# N571P032_v3 register map
File version: 1.0
Registers are 32-bit, read-write, reset 0x0 unless marked. A register's access mark holds for its fields unless they carry their own. Offsets are from the block's base; [hi:lo] are bit positions.

## SYS — SYS Register Map
Base 0x50000000
0x00 SYS_PDID ro reset 0xB320000 (reset mask 0xFFFF0000) — Product Identifier Register
  [15:0] IMG2 — Product Identifier. Data in MAP2 of information block are copied to this register after power on. MAP2 is used to store part number defined by Nuvoton.
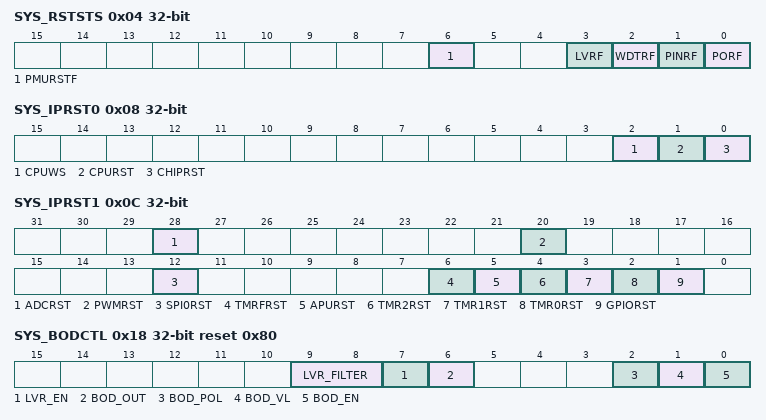
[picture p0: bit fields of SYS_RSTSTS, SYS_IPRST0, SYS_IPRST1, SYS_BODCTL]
0x04 SYS_RSTSTS (reset mask 0xFFFFFF00) — System Reset Source Register
  [6] PMURSTF — Reset Source From PMU. The PMURSTF flag is set by the reset signal from the PMU module to indicate the previous reset source. Note: Write 1 to clear this bit to 0.
    0=No reset from PMU; 1=The PMU has issued the reset signal to reset the system
  [3] LVRF — LVR Reset Flag. The LVR reset flag is set by the "Reset Signal" from the Low Voltage Reset Controller to indicate the previous reset source. Note: Write 1 to clear this bit to 0.
    0=No reset from LVR; 1=LVR controller had issued the reset signal to reset the system
  [2] WDTRF — Reset Source From WDG. The WDTRF flag is set if pervious reset source originates from the Watch-Dog module. Note: Write 1 to clear this bit to 0.
    0=No reset from Watch-Dog; 1=The Watch-Dog module issued the reset signal to reset the system
  [1] PINRF — nRESET Pin Reset Flag. The nRESET pin reset flag is set by the "Reset Signal" from the nRESET Pin to indicate the previous reset source. Note: Write 1 to clear this bit to 0.
    0=No reset from nRESET pin; 1=Pin nRESET had issued the reset signal to reset the system
  [0] PORF — POR Reset Flag. The POR reset flag is set by the "Reset Signal" from the Power-on Reset (POR) Controller to indicate the previous reset source. Note: Write 1 to clear this bit to 0.
    0=No reset from POR; 1=Power-on Reset (POR) Controller had issued the reset signal to reset the system
0x08 SYS_IPRST0 — IP Reset Control Resister0
  [2] CPUWS — CPU Wait-State Control For OTP Memory Access. Note: there must be 1 HCLK wait state if HCLK equal 23MHz.
    0=1 HCLK clock wait-state; 1=zero wait-state
  [1] CPURST — CPU Kernel One Shot Reset. Setting this bit will reset the CPU kernel and OTP Memory Controller(OMC), this bit will automatically return to "0" after the 2 clock cycles
    0=Normal; 1=Reset CPU
  [0] CHIPRST — CHIP One Shot Reset. Set this bit will reset the whole chip, this bit will automatically return to "0" after 2 clock cycles. CHIPRST is same as POR reset, all the chip modules are reset and the chip configuration settings from OTP are reloaded.
    0=Normal; 1=Reset CHIP
0x0C SYS_IPRST1 — IP Reset Control Resister1
  [28] ADCRST — ADC Controller Reset
    0=Normal Operation; 1=Reset
  [20] PWMRST — PWM Controller Reset
    0=Normal Operation; 1=Reset
  [12] SPI0RST — SPI0 Controller Reset
    0=Normal Operation; 1=Reset
  [6] TMRFRST — TimerF Controller Reset
    0=Normal operation; 1=Reset
  [5] APURST — APU Controller Reset
    0=Normal operation; 1=Reset
  [4] TMR2RST — Timer2 Controller Reset
    0=Normal operation; 1=Reset
  [3] TMR1RST — Timer1 Controller Reset
    0=Normal Operation; 1=Reset
  [2] TMR0RST — Timer0 Controller Reset
    0=Normal Operation; 1=Reset
  [1] GPIORST — GPIO Controller Reset
    0=Normal operation; 1=Reset
0x18 SYS_BODCTL reset 0x80 — Brown-Out Detector Control Register
  [9:8] LVR_FILTER
    0=LVR outputs without to be filtered; 1=LVR output will be filtered by 2 HCLK; 2=LVR output will be filtered by 8 HCLK; 3=LVR output will be filtered by 15 HCLK
  [7] LVR_EN — Low Voltage Reset (LVR) Enable (Protected Bit). The LVR function resets the chip when the input power voltage is lower than LVR circuit setting. LVR function is enabled in default.
    0=Disable LVR function; 1=Enable LVR function - After enable the bit, the LVR function will active with 100uS delay for LVR output stable
  [6] BOD_OUT — The Status for Brown-Out Detector Output It's a read only bit.
    0=The detected voltage is lower than BOD_VL setting. If the BOD_EN is "0", this bit always responses "0"; 1=The detected voltage is higher than BOD_VL setting
  [2] BOD_POL — Brown-Out Detector Output Polarity Select
    0=PB.15 will output the BOD out directly when PB.15 multi-function is active; 1=PB.15 will output the inverse of BOD out when PB.15 multi-function is active
  [1] BOD_VL — Brown-Out Detector Threshold Voltage Selection (Initiated & Protected Bit)
    0=Threshold voltage is 2.7V; 1=Threshold voltage is 3.0V
  [0] BOD_EN — Brown-Out Detector Enable (Initiated & Protected Bit)
    0=Brown-Out Detector function is disabled; 1=Brown-Out Detector function is enabled,
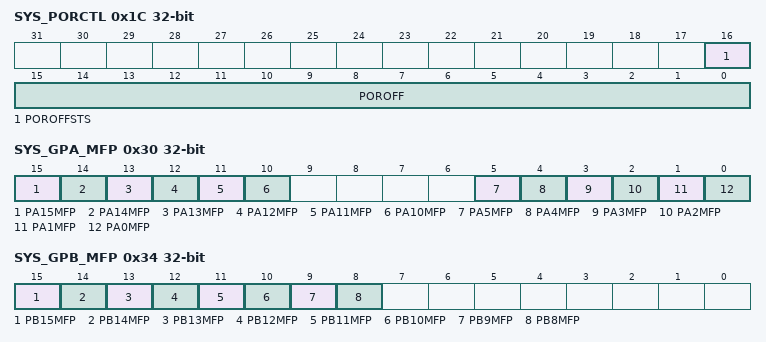
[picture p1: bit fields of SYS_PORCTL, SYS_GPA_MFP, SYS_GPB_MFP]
0x1C SYS_PORCTL — Power-On-Reset Controller Register
  [16] POROFFSTS — This bit is status bit of POR, it is read only.
    0=POR is active now; 1=POR is non-active now while POROFF equals 0x5aa5
  [15:0] POROFF — Power-On Reset Enable Code (Write Protect). When powered on, the POR circuit generates a reset signal to reset the whole chip function, but noise on the power may cause the POR active again. User can disable internal POR circuit to avoid unpredictable noise to cause chip reset by writing 0x5AA5 to this field. The POR function will be active again when this field is set to another value or chip is reset by other reset source, including: nRESET, Watchdog, LVR reset, ICE reset command and the software-chip reset function.
0x30 SYS_GPA_MFP — GPIO PA Multiple Alternate Functions and Input Type Control Register
  [15] PA15MFP
    0=The GPIOA-15 is selected to the pin PA.15; 1=PGC Reference Voltage pin
  [14] PA14MFP
    0=The GPIOA-14 is selected to the pin PA.14; 1=MIC Bias pin
  [13] PA13MFP
    0=The GPIOA-13 is selected to the pin PA.13; 1=Mic. IN- pin to Pre-Amp
  [12] PA12MFP
    0=The GPIOA-12 is selected to the pin PA.12; 1=Mic. IN+ pin to Pre-Amp
  [11] PA11MFP
    0=The GPIOA-11 is selected to the pin PA.11; 1=ADC input channel 3
  [10] PA10MFP
    0=The GPIOA-10 is selected to the pin PA.10; 1=ADC input channel 2
  [5] PA5MFP
    0=The GPIOA-5 is selected to the pin PA.5; 1=Timer0 counter external input
  [4] PA4MFP
    0=The GPIOA-4 is selected to the pin PA.4; 1=SPI0 data output
  [3] PA3MFP
    0=The GPIOA-3 is selected to the pin PA.3; 1=SPI0 data input
  [2] PA2MFP
    0=The GPIOA-2 is selected to the pin PA.2; 1=SPI0 clock output
  [1] PA1MFP
    0=The GPIOA-1 is selected to the pin PA.1; 1=SPI0 1st chip select output
  [0] PA0MFP
    0=The GPIOA-0 is selected to the pin PA.0; 1=SPI0 2nd chip select output
0x34 SYS_GPB_MFP — GPIO PB Multiple Alternate Functions and Input Type Control Register
  [15] PB15MFP
    0=The GPIOB-15 is selected to the pin PB.15; 1=BOD active signal output
  [14] PB14MFP
    0=The GPIOB-14 is selected to the pin PB.14; 1=Timer1 counter external input
  [13] PB13MFP
    0=The GPIOB-13 is selected to the pin PB.13; 1=IR carrier output
  [12] PB12MFP
    0=The GPIOB-12 is selected to the pin PB.12; 1=PWM timer capture input
  [11] PB11MFP
    0=The GPIOB-11 is selected to the pin PB.11; 1=PWM output pin 3
  [10] PB10MFP
    0=The GPIOB-10 is selected to the pin PB.10; 1=PWM output pin 2
  [9] PB9MFP
    0=The GPIOB-9 is selected to the pin PB.9; 1=PWM output pin 1
  [8] PB8MFP
    0=The GPIOB-8 is selected to the pin PB.8; 1=PWM output pin 0
0x38 SYS_GPA_HS — PA.4 ~ PA.0 High Speed Transition Control Register
  [4:0] GPA_HS
0x40 SYS_ICE_MFP reset 0x1 — ICE Multi-Function-Pin Controller Register
  [0] ICE_EN — This bit will set ICE_CLK & ICE_DAT pins to be serial debug wires or PB.4/5
    0=ICE_CLK and ICE_DAT will be assigned as PB.4 and PB.5, for general IO purpose; 1=ICE_CLK and ICE_DAT will be set as ICE CLCOK/ ICE DIO, only for debugging purpose
0xF4 SYS_DEVICEID ro reset 0x3E61 — Device ID Register
  [15:0] DEVICEID — Device ID Data. This register provides specific read-only information for the Device ID
0xFC SYS_IMGMAP1 ro reset not defined — MAP1 Data Image Register
  [31:0] IMG1 — Data Image of MAP1. Data in MAP1 of information block are copied to this register after power on.
0x100 SYS_REGLCTL — Register Lock Control Register
  [0] REGLCTL ro — Protected Register Lock/Unlock Index (Read Only). SPI0_RCLK - address 0x4003_0030. WDT_CTL -- address 0x4000_4000
    0=Protected registers are locked. Any write to the target register is ignored; 1=Protected registers are unlocked
  [7:0] SYS_REGLCTL wo — Register Lock Control Code (Write Only). Some registers have write-protection function. Writing these registers have to disable the protected function by writing the sequence value "59h", "16h", "88h" to this field. After this sequence is completed, the REGLCTL bit will be set to 1 and write-protection registers can be normal write.
0x120 SYS_PA_ADJ reset 0x10 — PA Offset Voltage Adjustment Register
  [5:0] PADCADJ — Turning the Offset voltage between SPKP/SPKN. PADCADJ[5] is selection bit, PADCADJ[4:0] are offset trim bits.
